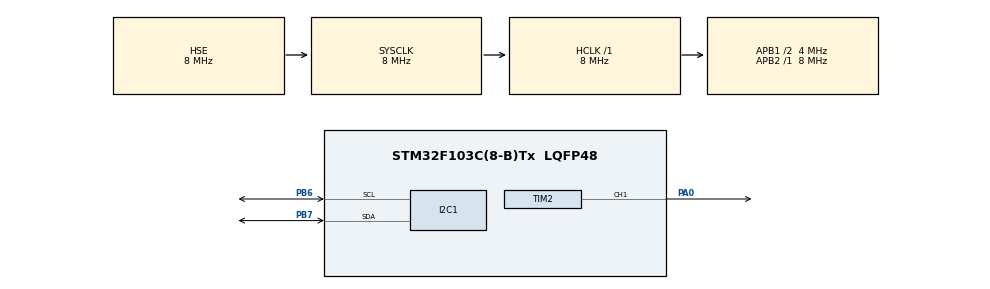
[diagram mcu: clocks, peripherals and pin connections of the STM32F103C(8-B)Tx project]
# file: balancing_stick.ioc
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FREERTOS.Tasks01=defaultTask,0,128,StartDefaultTask,Default,NULL,Dynamic,NULL,NULL;myTask02,-3,128,StartTask02,Default,NULL,Dynamic,NULL,NULL
FREERTOS.configUSE_NEWLIB_REENTRANT=1
I2C1.OwnAddress=0x29
Mcu.Family=STM32F1
Mcu.Name=STM32F103C(8-B)Tx
Mcu.Package=LQFP48
NVIC.PriorityGroup=NVIC_PRIORITYGROUP_4
NVIC.TIM1_UP_IRQn=true\:15\:0\:false\:false\:true\:false\:false\:true\:true
NVIC.TimeBase=TIM1_UP_IRQn
NVIC.TimeBaseIP=TIM1
PA0-WKUP.Signal=S_TIM2_CH1_ETR
PA13.Mode=Trace_Asynchronous_SW
PA13.Signal=SYS_JTMS-SWDIO
PA14.Mode=Trace_Asynchronous_SW
PA14.Signal=SYS_JTCK-SWCLK
PB3.Mode=Trace_Asynchronous_SW
PB3.Signal=SYS_JTDO-TRACESWO
PB6.Mode=I2C
PB6.Signal=I2C1_SCL
PB7.Mode=I2C
PB7.Signal=I2C1_SDA
PD0-OSC_IN.Mode=HSE-External-Oscillator
PD0-OSC_IN.Signal=RCC_OSC_IN
PD1-OSC_OUT.Mode=HSE-External-Oscillator
PD1-OSC_OUT.Signal=RCC_OSC_OUT
ProjectManager.HeapSize=0x200
ProjectManager.StackSize=0x400
ProjectManager.TargetToolchain=STM32CubeIDE
RCC.AHBFreq_Value=8000000
RCC.APB1CLKDivider=RCC_HCLK_DIV2
RCC.APB1Freq_Value=4000000
RCC.APB1TimFreq_Value=8000000
RCC.APB2Freq_Value=8000000
RCC.APB2TimFreq_Value=8000000
RCC.HCLKFreq_Value=8000000
RCC.PLLMUL=RCC_PLL_MUL9
RCC.PLLSourceVirtual=RCC_PLLSOURCE_HSE
RCC.SYSCLKFreq_VALUE=8000000
RCC.SYSCLKSource=RCC_SYSCLKSOURCE_HSE
RCC.USBFreq_Value=72000000
SH.S_TIM2_CH1_ETR.0=TIM2_CH1,PWM Generation1 CH1
TIM2.Channel-PWM\ Generation1\ CH1=TIM_CHANNEL_1
TIM2.OCPolarity_1=TIM_OCPOLARITY_LOW
TIM2.Period=20000
TIM2.Prescaler=8
TIM2.Pulse-PWM\ Generation1\ CH1=1500
VP_FREERTOS_VS_CMSIS_V1.Mode=CMSIS_V1
VP_SYS_VS_tim1.Mode=TIM1
board=custom

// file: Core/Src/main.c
/* USER CODE BEGIN Header */
/**
 ******************************************************************************
 * @file           : main.c
 * @brief          : Main program body
 ******************************************************************************
 * @attention
 *
 * Copyright (c) 2024 STMicroelectronics.
 * All rights reserved.
 *
 * This software is licensed under terms that can be found in the LICENSE file
 * in the root directory of this software component.
 * If no LICENSE file comes with this software, it is provided AS-IS.
 *
 ******************************************************************************
 */
/* USER CODE END Header */
#include "main.h"
#include "cmsis_os.h"

/* USER CODE BEGIN Includes */
#include "bno055.h"
/* USER CODE END Includes */

/* USER CODE BEGIN PD */
s8 BNO055_I2C_bus_read(u8 dev_addr, u8 reg_addr, u8 *reg_data, u8 cnt);
s8 BNO055_I2C_bus_write(u8 dev_addr, u8 reg_addr, u8 *reg_data, u8 cnt);
void BNO055_delay_msek(u32 msek);

/* USER CODE END PD */

I2C_HandleTypeDef hi2c1;

TIM_HandleTypeDef htim2;

osThreadId defaultTaskHandle;

void SystemClock_Config(void);
static void MX_GPIO_Init(void);
static void MX_I2C1_Init(void);
static void MX_TIM2_Init(void);
void StartDefaultTask(void const * argument);
void StartTask02(void const * argument);

int main(void)
{

  /* MCU Configuration--------------------------------------------------------*/

  /* Reset of all peripherals, Initializes the Flash interface and the Systick. */
  HAL_Init();

  /* Configure the system clock */
  SystemClock_Config();

  /* Initialize all configured peripherals */
  MX_GPIO_Init();
  MX_I2C1_Init();
  MX_TIM2_Init();

  /* Create the thread(s) */
  /* definition and creation of defaultTask */
  osThreadDef(defaultTask, StartDefaultTask, osPriorityNormal, 0, 128);
  defaultTaskHandle = osThreadCreate(osThread(defaultTask), NULL);

  /* Start scheduler */
  osKernelStart();

  /* We should never get here as control is now taken by the scheduler */

  /* Infinite loop */
	while (1) {

	}
}

void SystemClock_Config(void)
{
  RCC_OscInitTypeDef RCC_OscInitStruct = {0};
  RCC_ClkInitTypeDef RCC_ClkInitStruct = {0};

  /** Initializes the RCC Oscillators according to the specified parameters
  * in the RCC_OscInitTypeDef structure.
  */
  RCC_OscInitStruct.OscillatorType = RCC_OSCILLATORTYPE_HSE;
  RCC_OscInitStruct.HSEState = RCC_HSE_ON;
  RCC_OscInitStruct.PLL.PLLState = RCC_PLL_NONE;
  if (HAL_RCC_OscConfig(&RCC_OscInitStruct) != HAL_OK)
  {
    Error_Handler();
  }

  /** Initializes the CPU, AHB and APB buses clocks
  */
  RCC_ClkInitStruct.ClockType = RCC_CLOCKTYPE_HCLK|RCC_CLOCKTYPE_SYSCLK
                              |RCC_CLOCKTYPE_PCLK1|RCC_CLOCKTYPE_PCLK2;
  RCC_ClkInitStruct.SYSCLKSource = RCC_SYSCLKSOURCE_HSE;
  RCC_ClkInitStruct.AHBCLKDivider = RCC_SYSCLK_DIV1;
  RCC_ClkInitStruct.APB1CLKDivider = RCC_HCLK_DIV2;
  RCC_ClkInitStruct.APB2CLKDivider = RCC_HCLK_DIV1;

  if (HAL_RCC_ClockConfig(&RCC_ClkInitStruct, FLASH_LATENCY_0) != HAL_OK)
  {
    Error_Handler();
  }
}

static void MX_I2C1_Init(void)
{

  hi2c1.Instance = I2C1;
  hi2c1.Init.ClockSpeed = 100000;
  hi2c1.Init.DutyCycle = I2C_DUTYCYCLE_2;
  hi2c1.Init.OwnAddress1 = 0x29;
  hi2c1.Init.AddressingMode = I2C_ADDRESSINGMODE_7BIT;
  hi2c1.Init.DualAddressMode = I2C_DUALADDRESS_DISABLE;
  hi2c1.Init.OwnAddress2 = 0;
  hi2c1.Init.GeneralCallMode = I2C_GENERALCALL_DISABLE;
  hi2c1.Init.NoStretchMode = I2C_NOSTRETCH_DISABLE;
  if (HAL_I2C_Init(&hi2c1) != HAL_OK)
  {
    Error_Handler();
  }

}

static void MX_TIM2_Init(void)
{

  TIM_MasterConfigTypeDef sMasterConfig = {0};
  TIM_OC_InitTypeDef sConfigOC = {0};

  htim2.Instance = TIM2;
  htim2.Init.Prescaler = 8;
  htim2.Init.CounterMode = TIM_COUNTERMODE_UP;
  htim2.Init.Period = 20000;
  htim2.Init.ClockDivision = TIM_CLOCKDIVISION_DIV1;
  htim2.Init.AutoReloadPreload = TIM_AUTORELOAD_PRELOAD_DISABLE;
  if (HAL_TIM_PWM_Init(&htim2) != HAL_OK)
  {
    Error_Handler();
  }
  sMasterConfig.MasterOutputTrigger = TIM_TRGO_RESET;
  sMasterConfig.MasterSlaveMode = TIM_MASTERSLAVEMODE_DISABLE;
  if (HAL_TIMEx_MasterConfigSynchronization(&htim2, &sMasterConfig) != HAL_OK)
  {
    Error_Handler();
  }
  sConfigOC.OCMode = TIM_OCMODE_PWM1;
  sConfigOC.Pulse = 1500;
  sConfigOC.OCPolarity = TIM_OCPOLARITY_LOW;
  sConfigOC.OCFastMode = TIM_OCFAST_DISABLE;
  if (HAL_TIM_PWM_ConfigChannel(&htim2, &sConfigOC, TIM_CHANNEL_1) != HAL_OK)
  {
    Error_Handler();
  }
  HAL_TIM_MspPostInit(&htim2);

}

static void MX_GPIO_Init(void)
{

  /* GPIO Ports Clock Enable */
  __HAL_RCC_GPIOD_CLK_ENABLE();
  __HAL_RCC_GPIOA_CLK_ENABLE();
  __HAL_RCC_GPIOB_CLK_ENABLE();

}

/* USER CODE BEGIN 4 */

/************** I2C buffer length******/

#define I2C_BUFFER_LEN 8
#define I2C0           5

/*-------------------------------------------------------------------*
 *
 *  This is a sample code for read and write the data by using I2C
 *  Use either I2C  based on your need
 *  The device address defined in the bno055.h file
 *
 *--------------------------------------------------------------------*/

/*  \Brief: The API is used as I2C bus write
 *  \Return : Status of the I2C write
 *  \param dev_addr : The device address of the sensor
 *  \param reg_addr : Address of the first register,
 *   will data is going to be written
 *  \param reg_data : It is a value hold in the array,
 *      will be used for write the value into the register
 *  \param cnt : The no of byte of data to be write
 */
s8 BNO055_I2C_bus_write(u8 dev_addr, u8 reg_addr, u8 *reg_data, u8 cnt)
{
    s32 BNO055_iERROR = BNO055_INIT_VALUE;
    u8 array[I2C_BUFFER_LEN];
    u8 stringpos = BNO055_INIT_VALUE;

    array[BNO055_INIT_VALUE] = reg_addr;
    for (stringpos = BNO055_INIT_VALUE; stringpos < cnt; stringpos++)
    {
        array[stringpos] = *(reg_data + stringpos);
    }
    HAL_StatusTypeDef st_return = HAL_I2C_Mem_Write(&hi2c1, dev_addr,reg_addr,8, array,I2C_BUFFER_LEN , 10000);
    if(st_return==HAL_OK){
    	BNO055_iERROR= 	BNO055_SUCCESS;

    }
    else{
    	BNO055_iERROR= 	BNO055_ERROR;
    }
    return (s8)BNO055_iERROR;
}

/*  \Brief: The API is used as I2C bus read
 *  \Return : Status of the I2C read
 *  \param dev_addr : The device address of the sensor
 *  \param reg_addr : Address of the first register,
 *  will data is going to be read
 *  \param reg_data : This data read from the sensor,
 *   which is hold in an array
 *  \param cnt : The no of byte of data to be read
 */

s8 BNO055_I2C_bus_read(u8 dev_addr, u8 reg_addr, u8 *reg_data, u8 cnt)
{
    /* Please take the below API as your reference
     * for read the data using I2C communication
     * add your I2C read API here.
     * "BNO055_iERROR = I2C_WRITE_READ_STRING(DEV_ADDR,
     * ARRAY, ARRAY, 1, CNT)"
     * BNO055_iERROR is an return value of SPI write API
     * Please select your valid return value
     * In the driver BNO055_SUCCESS defined as 0
     * and FAILURE defined as -1
     */

    s32 BNO055_iERROR = BNO055_INIT_VALUE;
    u8 array[I2C_BUFFER_LEN] = { BNO055_INIT_VALUE };
    u8 stringpos = BNO055_INIT_VALUE;

    array[BNO055_INIT_VALUE] = reg_addr;

    /* Please take the below API as your reference
     * for read the data using I2C communication
     * add your I2C read API here.
     * "BNO055_iERROR = I2C_WRITE_READ_STRING(DEV_ADDR,
     * ARRAY, ARRAY, 1, CNT)"
     * BNO055_iERROR is an return value of SPI write API
     * Please select your valid return value
     * In the driver BNO055_SUCCESS defined as 0
     * and FAILURE defined as -1
     */

    HAL_StatusTypeDef st_return = HAL_I2C_Mem_Read(&hi2c1, dev_addr,reg_addr,8, array,I2C_BUFFER_LEN , 10000);
        if(st_return==HAL_OK){
        	BNO055_iERROR= 	BNO055_SUCCESS;

        }
        else{
        	BNO055_iERROR= 	BNO055_ERROR;
        }
     for (stringpos = BNO055_INIT_VALUE; stringpos < cnt; stringpos++)
         {
            *(reg_data + stringpos) = array[stringpos];
         }
    return (s8)BNO055_iERROR;
}

/*  Brief : The delay routine
 *  \param : delay in ms
 */
void BNO055_delay_msek(u32 msek)
{
    osDelay(msek);
}

/* USER CODE END 4 */

void StartDefaultTask(void const * argument)
{
  /* USER CODE BEGIN 5 */
	/* Infinite loop */
	int i =500;
	float mult = 1;

    s32 comres = BNO055_ERROR;
    struct bno055_t bno055;
    bno055.bus_write = BNO055_I2C_bus_write;
    bno055.bus_read = BNO055_I2C_bus_read;
    bno055.delay_msec = BNO055_delay_msek;
    bno055.dev_addr = 0x29;

    comres = bno055_init(&bno055);

    comres += bno055_set_power_mode(BNO055_POWER_MODE_NORMAL);
    comres += bno055_set_operation_mode(BNO055_OPERATION_MODE_NDOF);

    float euler_h_deg = 0.0;
    comres += bno055_convert_float_euler_h_deg(&euler_h_deg);
    HAL_TIM_PWM_Start(&htim2, TIM_CHANNEL_1);
	for (;;) {
	    comres += bno055_convert_float_euler_h_deg(&euler_h_deg);

		//__HAL_TIM_SET_COMPARE(&htim2, TIM_CHANNEL_1, i);
		if (i <=500){
			mult = 1;
		}
		if (i >= 2200){
			mult=-1;
		}
		//i = i +mult*15;
		osDelay(25);
	}
  /* USER CODE END 5 */
}

void StartTask02(void const * argument)
{
  for(;;)
  {
    osDelay(1);
  }
}

void HAL_TIM_PeriodElapsedCallback(TIM_HandleTypeDef *htim)
{
  if (htim->Instance == TIM1) {
    HAL_IncTick();
  }
}

void Error_Handler(void)
{
	__disable_irq();
	while (1) {
	}
}
